# STM32F107 register map
File version: 1.1
CPU: CM3 r1p1, little endian, no MPU, no FPU, 4 interrupt priority bits
Registers are 32-bit, read-write, reset 0x0 unless marked. A register's access mark holds for its fields unless they carry their own. Offsets are from the block's base; [hi:lo] are bit positions.

## IWDG — Independent watchdog
Base 0x40003000
0x00 KR wo — Key register (IWDG_KR)
  [15:0] KEY — Key value
    0x5555=Unlock (Enable access to PR, RLR and WINR registers); 0xAAAA=Feed watchdog with RLR register value; 0xCCCC=Start the watchdog
0x04 PR — Prescaler register (IWDG_PR)
  [2:0] PR — Prescaler divider
    0=DivideBy4 (Divider /4); 1=DivideBy8 (Divider /8); 2=DivideBy16 (Divider /16); 3=DivideBy32 (Divider /32); 4=DivideBy64 (Divider /64); 5=DivideBy128 (Divider /128); other=DivideBy256 (Divider /256)
0x08 RLR reset 0xFFF — Reload register (IWDG_RLR)
  [11:0] RL — Watchdog counter reload value
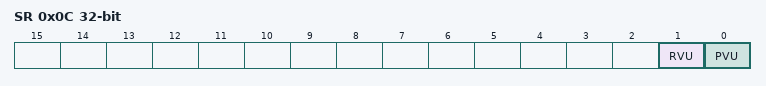
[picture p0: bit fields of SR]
0x0C SR ro — Status register (IWDG_SR)
  [1] RVU — Watchdog counter reload value update
  [0] PVU — Watchdog prescaler value update

## WWDG — Window watchdog
Base 0x40002C00
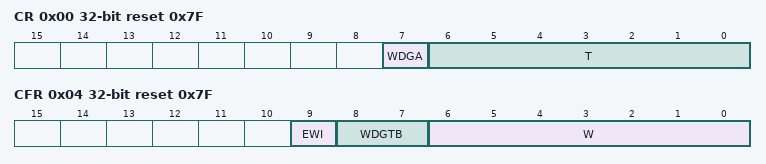
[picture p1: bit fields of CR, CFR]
0x00 CR reset 0x7F — Control register (WWDG_CR)
  [7] WDGA — Activation bit
    0=Disabled (Watchdog disabled); 1=Enabled (Watchdog enabled)
  [6:0] T — 7-bit counter (MSB to LSB)
0x04 CFR reset 0x7F — Configuration register (WWDG_CFR)
  [9] EWI — Early Wakeup Interrupt
    on write: 1=Enable (interrupt occurs whenever the counter reaches the value 0x40)
  [8:7] WDGTB — Timer Base
    0=Div1 (Counter clock (PCLK1 div 4096) div 1); 1=Div2 (Counter clock (PCLK1 div 4096) div 2); 2=Div4 (Counter clock (PCLK1 div 4096) div 4); 3=Div8 (Counter clock (PCLK1 div 4096) div 8)
  [6:0] W — 7-bit window value
0x08 SR — Status register (WWDG_SR)
  [0] EWIF write-0-clears — Early Wakeup Interrupt
    on read: 0=Finished (The EWI Interrupt Service Routine has been serviced); 1=Pending (The EWI Interrupt Service Routine has been triggered) | on write: 0=Finished (The EWI Interrupt Service Routine has been serviced)

## TIM6 — Basic timer
Base 0x40001000
Same registers: TIM7 0x40001400
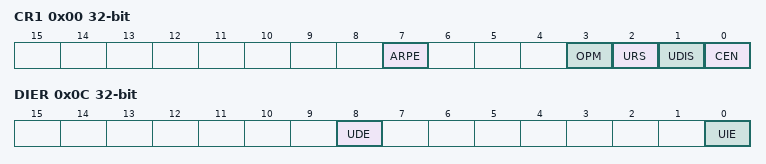
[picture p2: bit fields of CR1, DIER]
0x00 CR1 — control register 1
  [7] ARPE — Auto-reload preload enable
    0=Disabled (TIMx_APRR register is not buffered); 1=Enabled (TIMx_APRR register is buffered)
  [3] OPM — One-pulse mode
    0=Disabled (Counter is not stopped at update event); 1=Enabled (Counter stops counting at the next update event (clearing the CEN bit))
  [2] URS — Update request source
    0=AnyEvent (Any of counter overflow/underflow, setting UG, or update through slave mode, generates an update interrupt or DMA request); 1=CounterOnly (Only counter overflow/underflow generates an update interrupt or DMA request)
  [1] UDIS — Update disable
    0=Enabled (Update event enabled); 1=Disabled (Update event disabled)
  [0] CEN — Counter enable
    0=Disabled (Counter disabled); 1=Enabled (Counter enabled)
0x04 CR2 — control register 2
  [6:4] MMS — Master mode selection
    0=Reset (Use UG bit from TIMx_EGR register); 1=Enable (Use CNT bit from TIMx_CEN register); 2=Update (Use the update event)
0x0C DIER — DMA/Interrupt enable register
  [8] UDE — Update DMA request enable
    0=Disabled (Update DMA request disabled); 1=Enabled (Update DMA request enabled)
  [0] UIE — Update interrupt enable
    0=Disabled (Update interrupt disabled); 1=Enabled (Update interrupt enabled)
0x10 SR — status register
  [0] UIF write-0-clears — Update interrupt flag
    on read: 0=NoUpdateOccurred; 1=UpdatePending (Update interrupt pending) | on write: 0=Clear flag
0x14 EGR wo — event generation register
  [0] UG — Update generation
    1=Update (Re-initializes the timer counter and generates an update of the registers.)
0x24 CNT — counter
  [15:0] CNT — Low counter value
0x28 PSC — prescaler
  [15:0] PSC — Prescaler value
0x2C ARR — auto-reload register
  [15:0] ARR — Low Auto-reload value

## Ethernet_MMC — Ethernet: MAC management counters
Base 0x40028100
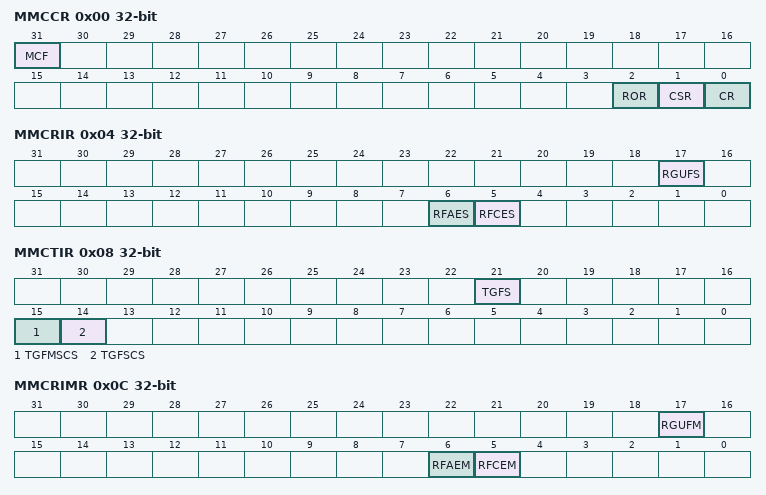
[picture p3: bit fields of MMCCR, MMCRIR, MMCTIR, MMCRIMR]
0x00 MMCCR — Ethernet MMC control register (ETH_MMCCR)
  [31] MCF — MMC counter freeze
    0=Unfrozen (All MMC counters update normally); 1=Frozen (All MMC counters frozen to their current value)
  [2] ROR — Reset on read
    0=Disabled (MMC counters do not reset on read); 1=Enabled (MMC counters reset to zero after read)
  [1] CSR — Counter stop rollover
    0=Disabled (Counters roll over to zero after reaching the maximum value); 1=Enabled (Counters do not roll over to zero after reaching the maximum value)
  [0] CR — Counter reset
    1=Reset all counters. Cleared automatically
0x04 MMCRIR — Ethernet MMC receive interrupt register (ETH_MMCRIR)
  [17] RGUFS — Received good Unicast frames status
  [6] RFAES — Received frames alignment error status
  [5] RFCES — Received frames CRC error status
0x08 MMCTIR — Ethernet MMC transmit interrupt register (ETH_MMCTIR)
  [21] TGFS — Transmitted good frames status
  [15] TGFMSCS — Transmitted good frames more than single collision status
  [14] TGFSCS — Transmitted good frames single collision status
0x0C MMCRIMR — Ethernet MMC receive interrupt mask register (ETH_MMCRIMR)
  [17] RGUFM — Received good Unicast frames mask
    0=Unmasked (Received-good-unicast counter half-full interrupt enabled); 1=Masked (Received-good-unicast counter half-full interrupt disabled)
  [6] RFAEM — Received frames alignment error mask
    0=Unmasked (Received-alignment-error counter half-full interrupt enabled); 1=Masked (Received-alignment-error counter half-full interrupt disabled)
  [5] RFCEM — Received frame CRC error mask
    0=Unmasked (Received-crc-error counter half-full interrupt enabled); 1=Masked (Received-crc-error counter half-full interrupt disabled)
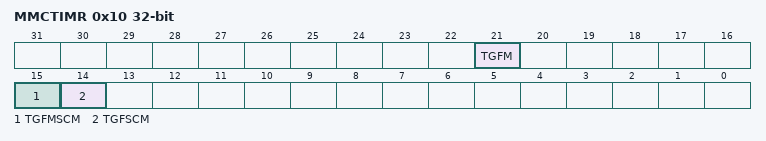
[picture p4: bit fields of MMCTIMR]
0x10 MMCTIMR — Ethernet MMC transmit interrupt mask register (ETH_MMCTIMR)
  [21] TGFM — Transmitted good frames mask
    0=Unmasked (Transmitted-good counter half-full interrupt enabled); 1=Masked (Transmitted-good counter half-full interrupt disabled)
  [15] TGFMSCM — Transmitted good frames more than single collision mask
    0=Unmasked (Transmitted-good-multiple-collision half-full interrupt enabled); 1=Masked (Transmitted-good-multiple-collision half-full interrupt disabled)
  [14] TGFSCM — Transmitted good frames single collision mask
    0=Unmasked (Transmitted-good-single-collision half-full interrupt enabled); 1=Masked (Transmitted-good-single-collision half-full interrupt disabled)
0x4C MMCTGFSCCR ro — Ethernet MMC transmitted good frames after a single collision counter
  [31:0] TGFSCC — Transmitted good frames single collision counter
0x50 MMCTGFMSCCR ro — Ethernet MMC transmitted good frames after more than a single collision
  [31:0] TGFMSCC — Transmitted good frames after more than a single collision counter
0x68 MMCTGFCR ro — Ethernet MMC transmitted good frames counter register
  [31:0] TGFC — Transmitted good frames counter
0x94 MMCRFCECR ro — Ethernet MMC received frames with CRC error counter register
  [31:0] RFCFC — Received frames with CRC error counter
0x98 MMCRFAECR ro — Ethernet MMC received frames with alignment error counter register
  [31:0] RFAEC — Received frames with alignment error counter
0xC4 MMCRGUFCR ro — MMC received good unicast frames counter register
  [31:0] RGUFC — Received good unicast frames counter
